AUTOSAR XML (schema 4-3-0)
package /ComponentTypes
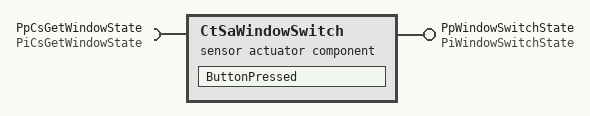
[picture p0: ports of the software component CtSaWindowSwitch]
  sensor actuator sw component type CtSaWindowSwitch
    provide port PpWindowSwitchState: nonqueued-sender-com-spec{data-element=DeWindowSwitchState, init-value=0}, provided-interface=PiWindowSwitchState
    require port PpCsGetWindowState: required-com-specs=[Operation, ReadFromWindowState], required-interface=PiCsGetWindowState
    behavior CtSaWindowSwitch_InternalBehavior
      runnable ButtonPressed
        executable entity activation reason ActReason_0: bit-position=0
        data-send-points:
          access SEND_PpWindowSwitchState_DeWindowSwitchState: accessed-variable=PpWindowSwitchState.DeWindowSwitchState
  swc implementation CtSaWindowSwitch_Implementation: behavior=CtSaWindowSwitch_InternalBehavior
